AUTOSAR XML (schema 00049)
package /RB/PT/PCT_ASW3/SwComponentTypes
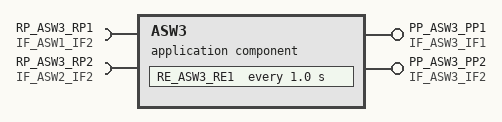
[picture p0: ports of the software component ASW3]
  application sw component type ASW3
    provide port PP_ASW3_PP1: provided-interface=IF_ASW3_IF1
    require port RP_ASW3_RP1: required-interface=IF_ASW1_IF2
    provide port PP_ASW3_PP2: provided-interface=IF_ASW3_IF2
    require port RP_ASW3_RP2: required-interface=IF_ASW2_IF2
    behavior IB_ASW3_IB1: data-type-mapping=[DTMS_ASW3_1, DTMS_ASW3_2]
      timing event TE_ASW3_TE1: start-on-event=RE_ASW3_RE1, period=1.0
      runnable RE_ASW3_RE1: symbol=ASW3_10ms
        data-receive-point-by-values:
          access DRP_ASW3_DRP1: accessed-variable=RP_ASW3_RP1.VDP_ASW1_Var2
          access DRP_ASW3_DRP2: accessed-variable=RP_ASW3_RP2.VDP_ASW2_Var2
        data-send-points:
          access DSP_ASW3_DSP1: accessed-variable=PP_ASW3_PP1.VDP_ASW3_Var1
          access DSP_ASW3_DSP2: accessed-variable=PP_ASW3_PP2.VDP_ASW3_Var2
package /RB/PT/PCT_ASW3/PortInterfaces
  4 x sender receiver interface:
    IF_ASW3_IF1
      data VDP_ASW3_Var1: type=ADT_ASW3_uint32
    IF_ASW1_IF2
      data VDP_ASW1_Var2: type=ADT_ASW1_uint32
    IF_ASW3_IF2
      data VDP_ASW3_Var2: type=ADT_ASW3_uint32
    IF_ASW2_IF2
      data VDP_ASW2_Var2: type=ADT_ASW2_uint32
package /RB/PT/PCT_ASW3/ApplicationDataTypes
  app type ADT_ASW3_uint32: category=VALUE, sw-calibration-access=READ-ONLY
package /RB/PT/PCT_ASW3/ImplementationDataTypes
  impl type IDT_ASW3_uint32: implementation-data-type=uint32
package /RB/PT/PCT_ASW3/DataTypeMappingSets
  data type mapping set DTMS_ASW3_1: data-type-map{application-data-type=ADT_ASW3_uint32, implementation-data-type=IDT_ASW3_uint32}
  data type mapping set DTMS_ASW3_2: data-type-map{application-data-type=ADT_ASW1_uint32, implementation-data-type=IDT_ASW1_uint32}
